AUTOSAR XML (schema 00050)
standard types defined: Boolean
package /ARRoot
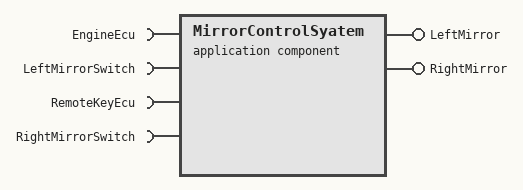
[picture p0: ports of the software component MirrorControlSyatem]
  application sw component type MirrorControlSyatem
    require port EngineEcu
    provide port LeftMirror
    require port LeftMirrorSwitch
    require port RemoteKeyEcu
    provide port RightMirror
    require port RightMirrorSwitch
    4 x behavior:
      MirrorControlSsystemIB
        6 x runnable:
          EngineEcuRunnable: external-triggering-point
          LeftMirrorRunnable: variable-access, external-triggering-point
          LeftMirrorSwitchRunnable: variable-access
          RemoteKeyEcuRunnable: variable-access
          RightMirrorRunnable: variable-access
          RightMirrorSwitchRunnable: variable-access
      MirrorLeftIB
      MirrorRightIB
      RemoteKeyIB
  client server interface MirrorControlSystemCSIF: client-server-operation
  sender receiver interface MirrorControlSystemSRIF
